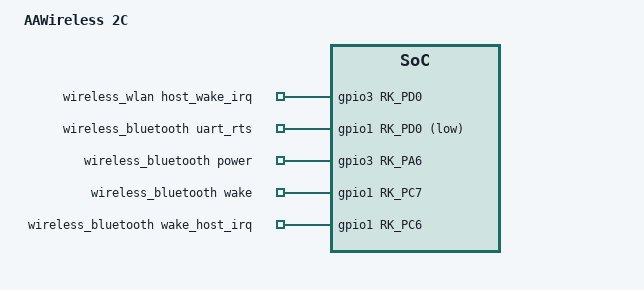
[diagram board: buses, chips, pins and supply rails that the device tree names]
// SPDX-License-Identifier: (GPL-2.0+ OR MIT)

/dts-v1/;

#include "aaw2b.dtsi"

/ {
	model = "AAWireless 2C";

	wireless_wlan: wireless-wlan {
		compatible = "wlan-platdata";
		pinctrl-names = "default";
		pinctrl-0 = <&wifi_wake_host>;
		WIFI,host_wake_irq = <&gpio3 RK_PD0 GPIO_ACTIVE_HIGH>;
		status = "okay";
	};

	wireless_bluetooth: wireless-bluetooth {
		compatible = "bluetooth-platdata";
		uart_rts_gpios = <&gpio1 RK_PD0 GPIO_ACTIVE_LOW>;
		BT,power_gpio = <&gpio3 RK_PA6 GPIO_ACTIVE_HIGH>;
		BT,wake_gpio = <&gpio1 RK_PC7 GPIO_ACTIVE_HIGH>;
		BT,wake_host_irq = <&gpio1 RK_PC6 GPIO_ACTIVE_HIGH>;
		pinctrl-names = "default", "rts_gpio";
		pinctrl-0 = <&uart5m1_rtsn &uart5m1_ctsn &bluetooth_enable>;
		pinctrl-1 = <&uart5m1_rtsn_gpio &bluetooth_enable>;
		status = "okay";
	};
};

&pinctrl {
	wireless-bluetooth {
		bluetooth_enable: bluetooth-enable {
			rockchip,pins = <3 RK_PA6 RK_FUNC_GPIO &pcfg_pull_none>, <1 RK_PC7 RK_FUNC_GPIO &pcfg_pull_none>;
		};
	};
};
